# XMC3050 register map
Vendor: Infineon; File version: 1.5.3 (Reference Manual v1.5)
CPU: CM4 r2p0, little endian, MPU, FPU, 6 interrupt priority bits
Registers are 32-bit, read-write, reset 0x0 unless marked. A register's access mark holds for its fields unless they carry their own. Offsets are from the block's base; [hi:lo] are bit positions; 'fields as' and 'values as' point back to an identical list.

## SCU_HIBERNATE — System Control Unit
Base 0x50004300
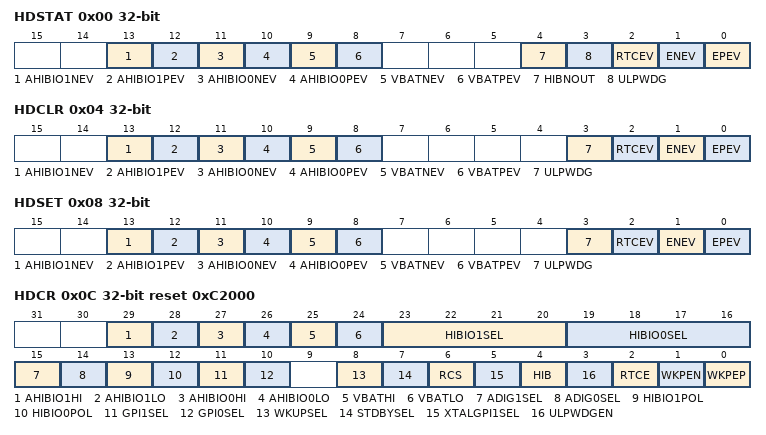
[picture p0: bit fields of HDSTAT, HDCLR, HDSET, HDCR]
0x00 HDSTAT ro — Hibernate Domain Status Register
  [13] AHIBIO1NEV — Wake-Up on LPAC Negative Edge of HIB_IO_1 Threshold Crossing
    0=Wake-up on falling below threshold event inactive; 1=Wake-up on falling below threshold event active
  [12] AHIBIO1PEV — Wake-Up on LPAC Positive Edge of HIB_IO_1 Threshold Crossing
    0=Wake-up on rising above threshold event inactive; 1=Wake-up on rising above threshold event active
  [11] AHIBIO0NEV — Wake-Up on LPAC Negative Edge of HIB_IO_0 Threshold Crossing
    values as AHIBIO1NEV
  [10] AHIBIO0PEV — Wake-Up on LPAC Positive Edge of HIB_IO_0 Threshold Crossing
    values as AHIBIO1PEV
  [9] VBATNEV — Wake-Up on LPAC Negative Edge of VBAT Threshold Crossing
    values as AHIBIO1NEV
  [8] VBATPEV — Wake-Up on LPAC Positive Edge of VBAT Threshold Crossing
    values as AHIBIO1PEV
  [4] HIBNOUT — Hibernate Control Status
    0=Hibernate not driven active to pads; 1=Hibernate driven active to pads
  [3] ULPWDG — ULP WDG Alarm Status
    0=Watchdog alarm did not occur; 1=Watchdog alarm occurred
  [2] RTCEV — RTC Event
    0=Wake-up on RTC event inactive; 1=Wake-up on RTC event active
  [1] ENEV — Wake-up Pin Event Negative Edge
    0=Wake-up on negative edge pin event inactive; 1=Wake-up on negative edge pin event active
  [0] EPEV — Wake-up Pin Event Positive Edge
    0=Wake-up on positive edge pin event inactive; 1=Wake-up on positive edge pin event active
0x04 HDCLR wo — Hibernate Domain Status Clear Register
  [13] AHIBIO1NEV — Wake-Up on LPAC Negative Edge of HIB_IO_1 Threshold Crossing Clear
    0=No effect; 1=Clear wake-up event
  [12] AHIBIO1PEV — Wake-Up on LPAC Positive Edge of HIB_IO_1 Threshold Crossing Clear
    0=No effect; 1=Clear wake-up event
  [11] AHIBIO0NEV — Wake-Up on LPAC Negative Edge of HIB_IO_0 Threshold Crossing Clear
    0=No effect; 1=Clear wake-up event
  [10] AHIBIO0PEV — Wake-Up on LPAC Positive Edge of HIB_IO_0 Threshold Crossing Clear
    0=No effect; 1=Clear wake-up event
  [9] VBATNEV — Wake-Up on LPAC Negative Edge of VBAT Threshold Crossing Clear
    0=No effect; 1=Clear wake-up event
  [8] VBATPEV — Wake-Up on LPAC Positive Edge of VBAT Threshold Crossing Clear
    0=No effect; 1=Clear wake-up event
  [3] ULPWDG — ULP WDG Alarm Clear
    0=No effect; 1=Clear watchdog alarm
  [2] RTCEV — RTC Event Clear
    0=No effect; 1=Clear wake-up event
  [1] ENEV — Wake-up Pin Event Negative Edge Clear
    0=No effect; 1=Clear wake-up event
  [0] EPEV — Wake-up Pin Event Positive Edge Clear
    0=No effect; 1=Clear wake-up event
0x08 HDSET wo — Hibernate Domain Status Set Register
  [13] AHIBIO1NEV — Wake-Up on LPAC Negative Edge of HIB_IO_1 Threshold Crossing Set
    0=No effect; 1=Set wake-up event
  [12] AHIBIO1PEV — Wake-Up on LPAC Positive Edge of HIB_IO_1 Threshold Crossing Set
    0=No effect; 1=Set wake-up event
  [11] AHIBIO0NEV — Wake-Up on LPAC Negative Edge of HIB_IO_0 Threshold Crossing Set
    0=No effect; 1=Set wake-up event
  [10] AHIBIO0PEV — Wake-Up on LPAC Positive Edge of HIB_IO_0 Threshold Crossing Set
    0=No effect; 1=Set wake-up event
  [9] VBATNEV — Wake-Up on LPAC Negative Edge of VBAT Threshold Crossing Set
    0=No effect; 1=Set wake-up event
  [8] VBATPEV — Wake-Up on LPAC Positive Edge of VBAT Threshold Crossing Set
    0=No effect; 1=Set wake-up event
  [3] ULPWDG — ULP WDG Alarm Set
    0=No effect; 1=Set watchdog alarm
  [2] RTCEV — RTC Event Set
    0=No effect; 1=Set wake-up event
  [1] ENEV — Wake-up Pin Event Negative Edge Set
    0=No effect; 1=Set wake-up event
  [0] EPEV — Wake-up Pin Event Positive Edge Set
    0=No effect; 1=Set wake-up event
0x0C HDCR reset 0xC2000 — Hibernate Domain Control Register
  [29] AHIBIO1HI — Wake-Up on Analog HIB_IO_1 Rising Above Threshold Enable
    0=Wake-up event disabled; 1=Wake-up event enabled
  [28] AHIBIO1LO — Wake-Up on Analog HIB_IO_1 Falling Below Threshold Enable
    0=Wake-up event disabled; 1=Wake-up event enabled
  [27] AHIBIO0HI — Wake-Up on Analog HIB_IO_0 Rising Above Threshold Enable
    0=Wake-up event disabled; 1=Wake-up event enabled
  [26] AHIBIO0LO — Wake-Up on Analog HIB_IO_0 Falling Below Threshold Enable
    0=Wake-up event disabled; 1=Wake-up event enabled
  [25] VBATHI — Wake-Up on VBAT Rising Above Threshold Enable
    0=Wake-up event disabled; 1=Wake-up event enabled
  [24] VBATLO — Wake-Up on VBAT Falling Below Threshold Enable
    0=Wake-up event disabled; 1=Wake-up event enabled
  [23:20] HIBIO1SEL — HIB_IO_1 Pin I/O Control (Default WKUP)
    0=Direct input, No input pull device connected; 1=Direct input, Input pull-down device connected; 2=Direct input, Input pull-up device connected; 8=Push-pull HIB Control output; 9=Push-pull WDT service output; 10=Push-pull GPIO output; 12=Open-drain HIB Control output; 13=Open-drain WDT service output; 14=Open-drain GPIO output; 15=Analog input
  [19:16] HIBIO0SEL — HIB_IO_0 Pin I/O Control (default HIBOUT)
    values as HIBIO1SEL
  [15] ADIG1SEL — Select Analog Channel 1 or Digital Output Path
    0=Digital input; 1=Analog comparator result for HIB_IO_1
  [14] ADIG0SEL — Select Analog Channel 0 or Digital Output Path
    0=Digital input; 1=Analog comparator result for HIB_IO_0
  [13] HIBIO1POL — HIBIO1 Polarity Set
    0=Direct value; 1=Inverted value
  [12] HIBIO0POL — HIBIO0 Polarity Set
    0=Direct value; 1=Inverted value
  [11] GPI1SEL — General Purpose Input 1 Selection
    0=HIB_IO_1 pin selected; 1=HIB_IO_0 pin selected
  [10] GPI0SEL — General Purpose Input 0 Selection
    0=HIB_IO_1 pin selected; 1=HIB_IO_0 pin selected
  [8] WKUPSEL — Wake-Up from Hibernate Trigger Input Selection
    0=HIB_IO_1 pin selected; 1=HIB_IO_0 pin selected
  [7] STDBYSEL — fSTDBY Clock Selection
    0=fOSI selected; 1=fULP selected
  [6] RCS — fRTC Clock Selection
    0=fOSI selected; 1=fULP selected
  [5] XTALGPI1SEL — Multiplex Control for RTC_XTAL_1 Select as GPI Input
    0=RTC_XTAL_1 input selected; 1=Analog comparator output for HIB_IO_1 or pre-selected digital IO input
  [4] HIB — Hibernate Request Value Set
    0=External hibernate request inactive; 1=External hibernate request active
  [3] ULPWDGEN — ULP WDG Alarm Enable
    0=Wake-up event disabled; 1=Wake-up event enabled
  [2] RTCE — Wake-up on RTC Event Enable
    0=Wake-up event disabled; 1=Wake-up event enabled
  [1] WKPEN — Wake-up on Pin Event Negative Edge Enable
    0=Wake-up event disabled; 1=Wake-up event enabled
  [0] WKPEP — Wake-Up on Pin Event Positive Edge Enable
    0=Wake-up event disabled; 1=Wake-up event enabled
0x14 OSCSICTRL reset 0x1 — fOSI Control Register
  [0] PWD — Turn OFF the fOSI Clock Source
    0=Enabled; 1=Disabled
0x18 OSCULSTAT ro — OSC_ULP Status Register
  [0] X1D — XTAL1 Data Value
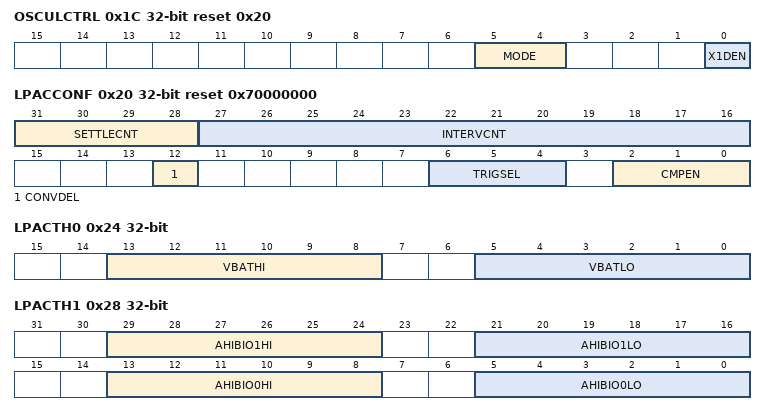
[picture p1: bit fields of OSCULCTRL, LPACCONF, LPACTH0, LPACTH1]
0x1C OSCULCTRL reset 0x20 — OSC_ULP Control Register
  [5:4] MODE — Oscillator Mode
    0=Oscillator is enabled, in operation; 1=Oscillator is enabled, in bypass mode; 2=Oscillator in power down; 3=Oscillator in power down, can be used as GPI
  [0] X1DEN — XTAL1 Data General Purpose Input Enable
    0=Data input inactivated, power down; 1=Data input active
0x20 LPACCONF reset 0x70000000 — Analog Wake-up Configuration Register
  [31:28] SETTLECNT — LPAC Settle Time Counter
  [27:16] INTERVCNT — Sub-second Interval Counter
  [12] CONVDEL — Conversion Delay
  [6:4] TRIGSEL — Analog Compare Trigger Select
    0=Sub-second interval counter; 1=RTC alarm event; 2=RTC periodic event; 3=On digital WKUP input positive edge event; 5=On digital WKUP input negative edge event; 6=Continuous measurement; 7=Single-shot on software request
  [2:0] CMPEN — Compare Enable for Input Selection
    0=Comparator permanently in power down; 1=Comparator activated for VBAT input; 2=Comparator activated for HIB_IO_0 input; 4=Comparator activated for HIB_IO_1 input
0x24 LPACTH0 — LPAC Threshold Register 0
  [13:8] VBATHI — VBAT Upper Threshold Value
  [5:0] VBATLO — VBAT Lower Threshold Value
0x28 LPACTH1 — LPAC Threshold Register 1
  [29:24] AHIBIO1HI — Analog HIB_IO_1 Upper Threshold Value
  [21:16] AHIBIO1LO — Analog HIB_IO_1 Lower Threshold Value
  [13:8] AHIBIO0HI — Analog HIB_IO_0 Upper Threshold Value
  [5:0] AHIBIO0LO — Analog HIB_IO_0 Lower Threshold Value
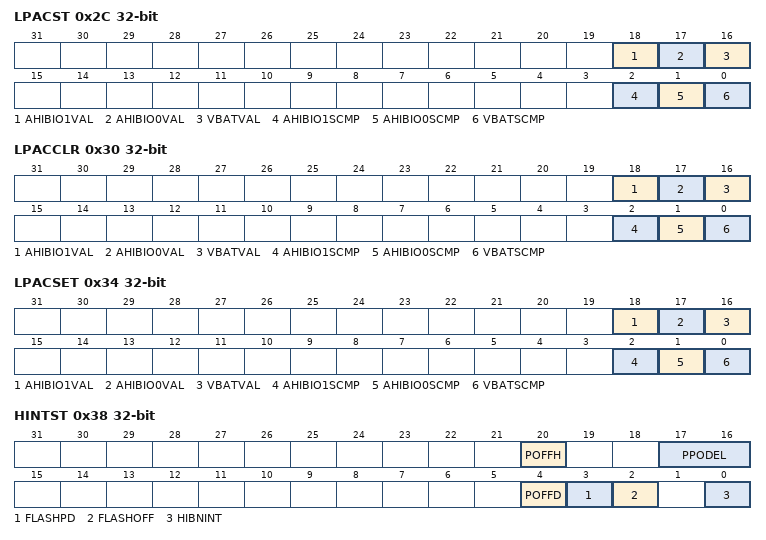
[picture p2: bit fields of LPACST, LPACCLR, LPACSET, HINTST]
0x2C LPACST ro — Hibernate Analog Control State Register
  [18] AHIBIO1VAL — HIB_IO_1 Input Compare Operation Result
    0=Below programmed threshold; 1=Above programmed threshold
  [17] AHIBIO0VAL — HIB_IO_0 Input Compare Operation Result
    0=Below programmed threshold; 1=Above programmed threshold
  [16] VBATVAL — VBAT Compare Operation Result
    0=Below programmed threshold; 1=Above programmed threshold
  [2] AHIBIO1SCMP — Trigger HIB_IO_1 Input Single Compare Operation Status
    0=Ready to start new compare operation; 1=Compare operation completed
  [1] AHIBIO0SCMP — Trigger HIB_IO_0 Input Single Compare Operation Status
    values as AHIBIO1SCMP
  [0] VBATSCMP — Trigger VBAT Single Compare Operation Status
    values as AHIBIO1SCMP
0x30 LPACCLR wo — LPAC Control Clear Register
  [18] AHIBIO1VAL — HIB_IO_1 Input Compare Initial Value Clear
    0=No effect; 1=Below programmed threshold
  [17] AHIBIO0VAL — HIB_IO_0 Input Compare Initial Value Clear
    0=No effect; 1=Below programmed threshold
  [16] VBATVAL — VBAT Compare Operation Initial Value Clear
    0=No effect; 1=Below programmed threshold
  [2] AHIBIO1SCMP — Trigger HIB_IO_1 Input Single Compare Operation Clear
    0=No effect; 1=Clear the sticky bit
  [1] AHIBIO0SCMP — Trigger HIB_IO_0 Input Single Compare Operation Clear
    0=No effect; 1=Clear the sticky bit
  [0] VBATSCMP — Trigger VBAT Single Compare Operation Clear
    0=No effect; 1=Clear the sticky bit
0x34 LPACSET wo — LPAC Control Set Register
  [18] AHIBIO1VAL — HIB_IO_1 Input Compare Initial Value Set
    0=No effect; 1=Above programmed threshold
  [17] AHIBIO0VAL — HIB_IO_0 Input Compare Initial Value Set
    0=No effect; 1=Above programmed threshold
  [16] VBATVAL — VBAT Compare Operation Initial Value Set
    0=No effect; 1=Above programmed threshold
  [2] AHIBIO1SCMP — Trigger HIB_IO_1 Input Single Compare Operation Set
    0=No effect; 1=Start compare operation
  [1] AHIBIO0SCMP — Trigger HIB_IO_0 Input Single Compare Operation Set
    0=No effect; 1=Start compare operation
  [0] VBATSCMP — Trigger VBAT Single Compare Operation Set
    0=No effect; 1=Start compare operation
0x38 HINTST ro — Hibernate Internal Control State Register
  [20] POFFH — PORST Pull-up OFF in Hibernate Mode State
    0=Pull-up on; 1=Pull-up off
  [17:16] PPODEL — Delay on PORTS Pull-up Switching OFF on Hibernate Request
  [4] POFFD — PORST Pull-up OFF Direct Control State
    0=Pull-up on; 1=Pull-up off
  [3] FLASHPD — Flash Power Down State
    0=Normal mode; 1=Power down mode effectively entered
  [2] FLASHOFF — VDDP Supply Switch of Flash State
    0=VDDP supply of Flash switched on; 1=VDDP supply of Flash switched off
  [0] HIBNINT — Internally Controlled Hibernate Sequence Request State
    0=Hibernate not entered; 1=Hibernate entered
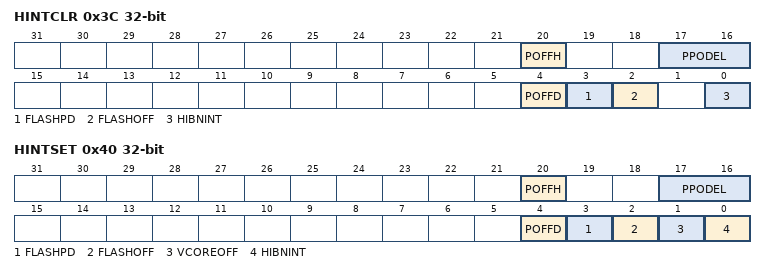
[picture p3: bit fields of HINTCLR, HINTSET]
0x3C HINTCLR wo — Hibernate Internal Control Clear Register
  [20] POFFH — PORST Pull-up OFF in Hibernate Mode Clear
    0=No effect; 1=Pull-up on
  [17:16] PPODEL — Delay on PORTS Pull-up Switching OFF on Hibernate Request Clear
  [4] POFFD — PORST Pull-up OFF Direct Control Clear
    0=No effect; 1=Pull-up on
  [3] FLASHPD — Flash Power Down Clear
    0=No effect; 1=Flash power down mode leave request
  [2] FLASHOFF — VDDP Supply Switch of Flash Clear
    0=No effect; 1=Switch on VDDP supply of Flash
  [0] HIBNINT — Internally Controlled Hibernate Sequence Request Clear
    0=No effect; 1=Hibernate bit clear
0x40 HINTSET wo — Hibernate Internal Control Set Register
  [20] POFFH — PORST Pull-up OFF in Hibernate Mode Set
    0=No effect; 1=Pull-up off
  [17:16] PPODEL — Delay on PORTS Pull-up Switching OFF on Hibernate Request Set
  [4] POFFD — PORST Pull-up OFF Direct Control Set
    0=No effect; 1=Pull-up off
  [3] FLASHPD — Flash Power Down Set
    0=No effect; 1=Flash power down mode request set
  [2] FLASHOFF — VDDP Supply Switch of Flash Set
    0=No effect; 1=Switch off VDDP supply of Flash
  [1] VCOREOFF — VDDC Generation off on EVR Set
    0=No effect; 1=VDDC off to EVR set
  [0] HIBNINT — Internally Controlled Hibernate Sequence Request Set
    0=No effect; 1=Hardware controlled hibernate sequence request active
